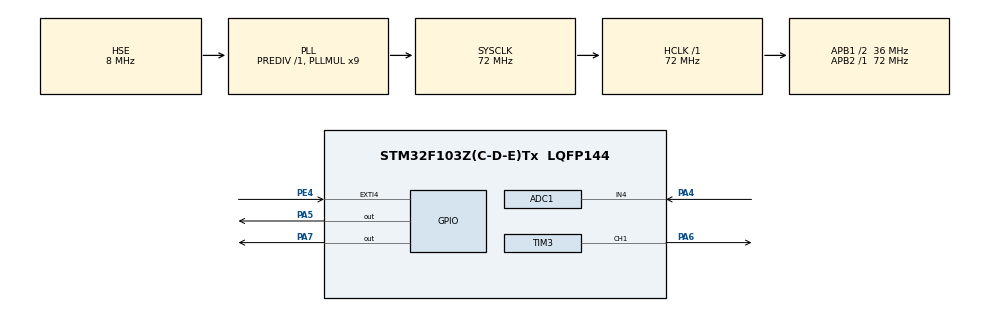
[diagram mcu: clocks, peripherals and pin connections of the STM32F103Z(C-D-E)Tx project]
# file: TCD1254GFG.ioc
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ADC1.Channel-1\#ChannelRegularConversion=ADC_CHANNEL_4
ADC1.ContinuousConvMode=DISABLE
ADC1.EnableRegularConversion=ENABLE
ADC1.ExternalTrigConv=ADC_SOFTWARE_START
ADC1.NbrOfConversion=1
ADC1.NbrOfConversionFlag=1
ADC1.Rank-1\#ChannelRegularConversion=1
ADC1.SamplingTime-1\#ChannelRegularConversion=ADC_SAMPLETIME_1CYCLE_5
ADC1.master=1
Mcu.Family=STM32F1
Mcu.Name=STM32F103Z(C-D-E)Tx
Mcu.Package=LQFP144
NVIC.EXTI4_IRQn=true\:0\:0\:false\:false\:true\:true\:true\:true
NVIC.PriorityGroup=NVIC_PRIORITYGROUP_4
NVIC.TIM3_IRQn=true\:15\:0\:true\:false\:true\:true\:true\:true
OSC_IN.Mode=HSE-External-Oscillator
OSC_IN.Signal=RCC_OSC_IN
OSC_OUT.Mode=HSE-External-Oscillator
OSC_OUT.Signal=RCC_OSC_OUT
PA13.Mode=Serial_Wire
PA13.Signal=SYS_JTMS-SWDIO
PA14.Mode=Serial_Wire
PA14.Signal=SYS_JTCK-SWCLK
PA4.Signal=ADCx_IN4
PA5.Signal=GPIO_Output
PA6.Signal=S_TIM3_CH1
PA7.Signal=GPIO_Output
PE4.GPIO_PuPd=GPIO_PULLUP
PE4.Signal=GPXTI4
ProjectManager.HeapSize=0x200
ProjectManager.StackSize=0x400
ProjectManager.TargetToolchain=MDK-ARM V5.32
RCC.ADCPresc=RCC_ADCPCLK2_DIV8
RCC.AHBFreq_Value=72000000
RCC.APB1CLKDivider=RCC_HCLK_DIV2
RCC.APB1Freq_Value=36000000
RCC.APB1TimFreq_Value=72000000
RCC.APB2Freq_Value=72000000
RCC.APB2TimFreq_Value=72000000
RCC.HCLKFreq_Value=72000000
RCC.PLLMUL=RCC_PLL_MUL9
RCC.PLLSourceVirtual=RCC_PLLSOURCE_HSE
RCC.SYSCLKFreq_VALUE=72000000
RCC.SYSCLKSource=RCC_SYSCLKSOURCE_PLLCLK
RCC.USBFreq_Value=72000000
SH.ADCx_IN4.0=ADC1_IN4,IN4
SH.S_TIM3_CH1.0=TIM3_CH1,PWM Generation1 CH1
TIM3.AutoReloadPreload=TIM_AUTORELOAD_PRELOAD_DISABLE
TIM3.Channel-PWM\ Generation1\ CH1=TIM_CHANNEL_1
TIM3.OCFastMode_PWM-PWM\ Generation1\ CH1=TIM_OCFAST_ENABLE
TIM3.OCPolarity_1=TIM_OCPOLARITY_HIGH
TIM3.Period=3
TIM3.Prescaler=17
TIM3.Pulse-PWM\ Generation1\ CH1=1
VP_ADC1_Vref_Input.Mode=IN-Vrefint
VP_TIM3_VS_ClockSourceINT.Mode=Internal
board=custom

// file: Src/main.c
/* USER CODE BEGIN Header */
/**
 ******************************************************************************
 * @file           : main.c
 * @brief          : Main program body
 ******************************************************************************
 * @attention
 *
 * Copyright (c) 2023 STMicroelectronics.
 * All rights reserved.
 *
 * This software is licensed under terms that can be found in the LICENSE file
 * in the root directory of this software component.
 * If no LICENSE file comes with this software, it is provided AS-IS.
 *
 ******************************************************************************
 */
/* USER CODE END Header */
#include "main.h"
#include "adc.h"
#include "tim.h"
#include "gpio.h"

/* USER CODE BEGIN Includes */
#include "tcddriver.h"
/* USER CODE END Includes */

/* USER CODE BEGIN PV */
tcddata tcdd;
float os_V_V_proportion;
/* USER CODE END PV */

void SystemClock_Config(void);

/* USER CODE BEGIN 0 */
void HAL_TIM_PeriodElapsedCallback(TIM_HandleTypeDef *htim)
{
    //TCD_RW(&tcdd, os_V_V_proportion);
}

void HAL_GPIO_EXTI_Callback(uint16_t GPIO_Pin)
{
    scanstart(&tcdd);
}
/* USER CODE END 0 */

int main(void)
{

  /* MCU Configuration--------------------------------------------------------*/

  /* Reset of all peripherals, Initializes the Flash interface and the Systick. */
  HAL_Init();

  /* Configure the system clock */
  SystemClock_Config();

  /* Initialize all configured peripherals */
  MX_GPIO_Init();
  MX_TIM3_Init();
  MX_ADC1_Init();
  /* USER CODE BEGIN 2 */
    os_V_V_proportion = init_vrefint_reciprocal();
    HAL_TIM_Base_Start_IT(&sclk);
    HAL_TIM_PWM_Start(&sclk, TIM_CHANNEL_1);
  /* USER CODE END 2 */

  /* Infinite loop */
  /* USER CODE BEGIN WHILE */
    while (1) {
        //scanstart(&tcdd);
    /* USER CODE END WHILE */

    /* USER CODE BEGIN 3 */
        //delay_ns(t3);
    }
  /* USER CODE END 3 */
}

void SystemClock_Config(void)
{
  RCC_OscInitTypeDef RCC_OscInitStruct = {0};
  RCC_ClkInitTypeDef RCC_ClkInitStruct = {0};
  RCC_PeriphCLKInitTypeDef PeriphClkInit = {0};

  /** Initializes the RCC Oscillators according to the specified parameters
  * in the RCC_OscInitTypeDef structure.
  */
  RCC_OscInitStruct.OscillatorType = RCC_OSCILLATORTYPE_HSE;
  RCC_OscInitStruct.HSEState = RCC_HSE_ON;
  RCC_OscInitStruct.HSEPredivValue = RCC_HSE_PREDIV_DIV1;
  RCC_OscInitStruct.HSIState = RCC_HSI_ON;
  RCC_OscInitStruct.PLL.PLLState = RCC_PLL_ON;
  RCC_OscInitStruct.PLL.PLLSource = RCC_PLLSOURCE_HSE;
  RCC_OscInitStruct.PLL.PLLMUL = RCC_PLL_MUL9;
  if (HAL_RCC_OscConfig(&RCC_OscInitStruct) != HAL_OK)
  {
    Error_Handler();
  }

  /** Initializes the CPU, AHB and APB buses clocks
  */
  RCC_ClkInitStruct.ClockType = RCC_CLOCKTYPE_HCLK|RCC_CLOCKTYPE_SYSCLK
                              |RCC_CLOCKTYPE_PCLK1|RCC_CLOCKTYPE_PCLK2;
  RCC_ClkInitStruct.SYSCLKSource = RCC_SYSCLKSOURCE_PLLCLK;
  RCC_ClkInitStruct.AHBCLKDivider = RCC_SYSCLK_DIV1;
  RCC_ClkInitStruct.APB1CLKDivider = RCC_HCLK_DIV2;
  RCC_ClkInitStruct.APB2CLKDivider = RCC_HCLK_DIV1;

  if (HAL_RCC_ClockConfig(&RCC_ClkInitStruct, FLASH_LATENCY_2) != HAL_OK)
  {
    Error_Handler();
  }
  PeriphClkInit.PeriphClockSelection = RCC_PERIPHCLK_ADC;
  PeriphClkInit.AdcClockSelection = RCC_ADCPCLK2_DIV8;
  if (HAL_RCCEx_PeriphCLKConfig(&PeriphClkInit) != HAL_OK)
  {
    Error_Handler();
  }
}

void Error_Handler(void)
{
    __disable_irq();
    while (1) {
    }
}
